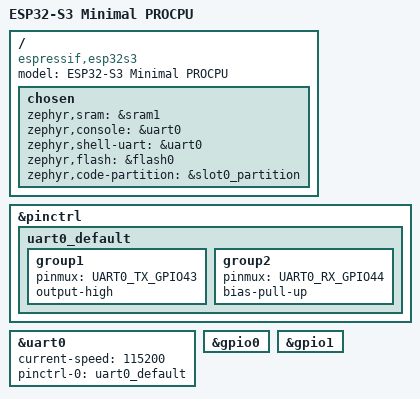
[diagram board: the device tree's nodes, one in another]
/dts-v1/;

#include <espressif/esp32s3/esp32s3_wroom_n8.dtsi>
#include <espressif/partitions_0x0_amp.dtsi>
#include <zephyr/dt-bindings/pinctrl/esp-pinctrl-common.h>
#include <dt-bindings/pinctrl/esp32s3-pinctrl.h>
#include <zephyr/dt-bindings/pinctrl/esp32s3-gpio-sigmap.h>

/ {
	model = "ESP32-S3 Minimal PROCPU";
	compatible = "espressif,esp32s3";

	chosen {
		zephyr,sram = &sram1;
		zephyr,console = &uart0;
		zephyr,shell-uart = &uart0;
		zephyr,flash = &flash0;
		zephyr,code-partition = &slot0_partition;
	};
};

&pinctrl {
	uart0_default: uart0_default {
		group1 {
			pinmux = <UART0_TX_GPIO43>;
			output-high;
		};
		group2 {
			pinmux = <UART0_RX_GPIO44>;
			bias-pull-up;
		};
	};
};

&uart0 {
	status = "okay";
	current-speed = <115200>;
	pinctrl-0 = <&uart0_default>;
	pinctrl-names = "default";
};

&gpio0 {
	status = "okay";
};

&gpio1 {
	status = "okay";
};
